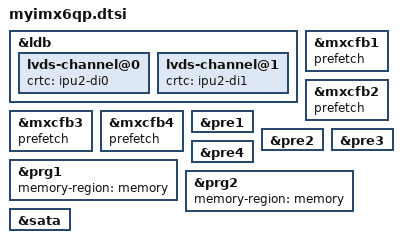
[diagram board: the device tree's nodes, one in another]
/*
 * MYZR Technology Co.,Ltd
 * http://www.myzr.com.cn
 * Tang Bin <tangb@myzr.com.cn>
 */

&ldb {
	lvds-channel@0 {
		crtc = "ipu2-di0";
	};

	lvds-channel@1 {
		crtc = "ipu2-di1";
	};
};

&mxcfb1 {
	prefetch;
};

&mxcfb2 {
	prefetch;
};

&mxcfb3 {
	prefetch;
};

&mxcfb4 {
	prefetch;
};

&pre1 {
	status = "okay";
};

&pre2 {
	status = "okay";
};

&pre3 {
	status = "okay";
};

&pre4 {
	status = "okay";
};

&prg1 {
	memory-region = <&memory>;
	status = "okay";
};

&prg2 {
	memory-region = <&memory>;
	status = "okay";
};

&sata {
	status = "okay";
};
